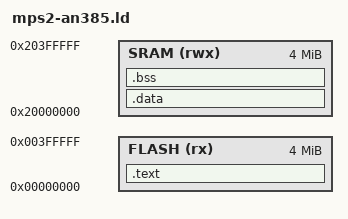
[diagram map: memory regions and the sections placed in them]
/* MPS2-AN385 Memory Map
 * Flash: 0x00000000 - 0x003FFFFF (4MB)
 * SRAM:  0x20000000 - 0x203FFFFF (4MB)
 */

ENTRY(Reset_Handler)

MEMORY {
    FLASH (rx)  : ORIGIN = 0x00000000, LENGTH = 4M
    SRAM  (rwx) : ORIGIN = 0x20000000, LENGTH = 4M
}

SECTIONS {
    .text : {
        KEEP(*(.vector_table))
        *(.text*)
        *(.rodata*)
        . = ALIGN(4);
        _etext = .;
    } > FLASH

    .data : AT(_etext) {
        _sdata = .;
        *(.data*)
        . = ALIGN(4);
        _edata = .;
    } > SRAM

    .bss : {
        _sbss = .;
        *(.bss*)
        *(COMMON)
        . = ALIGN(4);
        _ebss = .;
    } > SRAM

    _stack_top = ORIGIN(SRAM) + LENGTH(SRAM);
}
